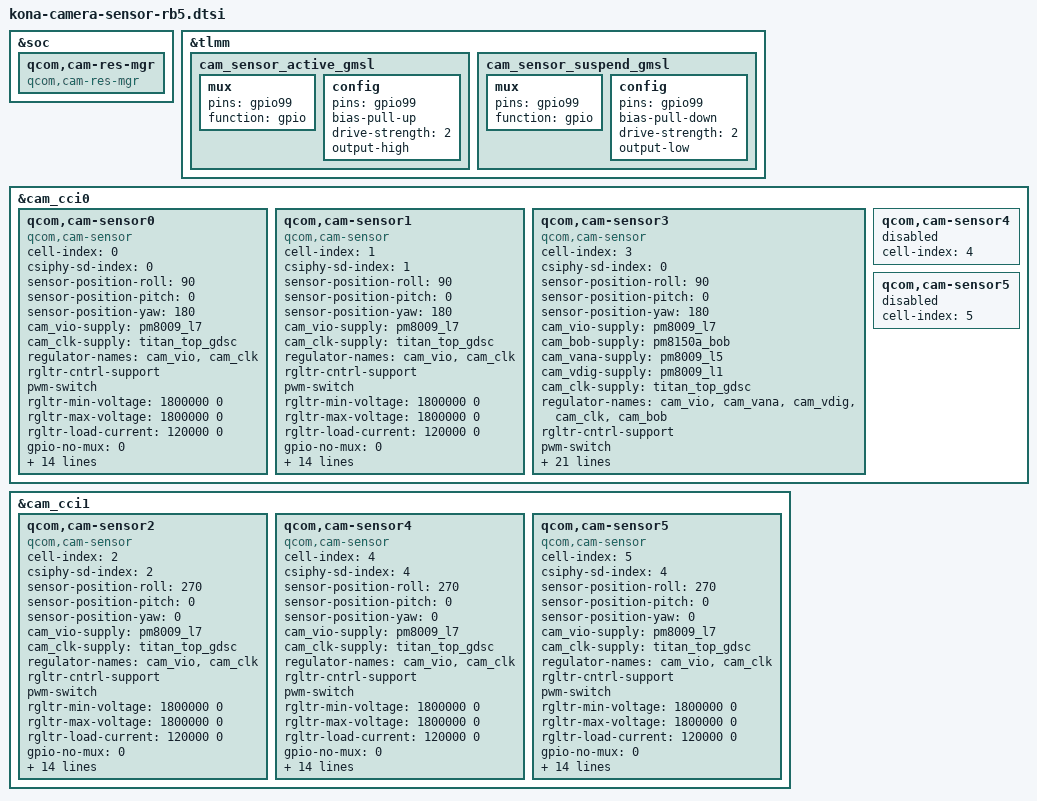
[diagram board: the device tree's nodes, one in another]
&soc {
	qcom,cam-res-mgr {
		compatible = "qcom,cam-res-mgr";
		status = "ok";
	};
};

&tlmm {
	cam_sensor_active_gmsl: cam_sensor_active_gmsl {
		/* RESET */
		mux {
			pins = "gpio99";
			function = "gpio";
		};

		config {
			pins = "gpio99";
			bias-pull-up;
			drive-strength = <2>; /* 2 MA */
			output-high;
		};
	};

	cam_sensor_suspend_gmsl: cam_sensor_suspend_gmsl {
		/* RESET */
		mux {
			pins = "gpio99";
			function = "gpio";
		};

		config {
			pins = "gpio99";
			bias-pull-down; /* PULL DOWN */
			drive-strength = <2>; /* 2 MA */
			output-low;
		};
	};
};

&cam_cci0 {
	qcom,cam-sensor0 {
		cell-index = <0>;
		compatible = "qcom,cam-sensor";
		csiphy-sd-index = <0>;
		sensor-position-roll = <90>;
		sensor-position-pitch = <0>;
		sensor-position-yaw = <180>;
		cam_vio-supply = <&pm8009_l7>;
		cam_clk-supply = <&titan_top_gdsc>;
		regulator-names = "cam_vio", "cam_clk";
		rgltr-cntrl-support;
		pwm-switch;
		rgltr-min-voltage = <1800000 0>;
		rgltr-max-voltage = <1800000 0>;
		rgltr-load-current = <120000 0>;
		gpio-no-mux = <0>;
		pinctrl-names = "cam_default", "cam_suspend";
		pinctrl-0 = <&cam_sensor_mclk0_active
				&cam_sensor_active_rear>;
		pinctrl-1 = <&cam_sensor_mclk0_suspend
				&cam_sensor_suspend_rear>;
		gpios = <&tlmm 94 0>,
			<&tlmm 93 0>;
		gpio-reset = <1>;
		gpio-req-tbl-num = <0 1>;
		gpio-req-tbl-flags = <1 0>;
		gpio-req-tbl-label = "CAMIF_MCLK0",
					"CAM_RESET0";
		sensor-mode = <0>;
		cci-master = <0>;
		status = "ok";
		clocks = <&clock_camcc CAM_CC_MCLK0_CLK>;
		clock-names = "cam_clk";
		clock-cntl-level = "turbo";
		clock-rates = <24000000>;
	};

	qcom,cam-sensor1 {
		cell-index = <1>;
		compatible = "qcom,cam-sensor";
		csiphy-sd-index = <1>;
		sensor-position-roll = <90>;
		sensor-position-pitch = <0>;
		sensor-position-yaw = <180>;
		cam_vio-supply = <&pm8009_l7>;
		cam_clk-supply = <&titan_top_gdsc>;
		regulator-names = "cam_vio", "cam_clk";
		rgltr-cntrl-support;
		pwm-switch;
		rgltr-min-voltage = <1800000 0>;
		rgltr-max-voltage = <1800000 0>;
		rgltr-load-current = <120000 0>;
		gpio-no-mux = <0>;
		pinctrl-names = "cam_default", "cam_suspend";
		pinctrl-0 = <&cam_sensor_mclk1_active
				&cam_sensor_active_rear_aux>;
		pinctrl-1 = <&cam_sensor_mclk1_suspend
				&cam_sensor_suspend_rear_aux>;
		gpios = <&tlmm 95 0>,
			<&tlmm 92 0>;
		gpio-reset = <1>;
		gpio-req-tbl-num = <0 1>;
		gpio-req-tbl-flags = <1 0>;
		gpio-req-tbl-label = "CAMIF_MCLK0",
					"CAM_RESET0";
		sensor-mode = <0>;
		cci-master = <1>;
		status = "ok";
		clocks = <&clock_camcc CAM_CC_MCLK1_CLK>;
		clock-names = "cam_clk";
		clock-cntl-level = "turbo";
		clock-rates = <24000000>;
	};

	qcom,cam-sensor3 {
		cell-index = <3>;
		compatible = "qcom,cam-sensor";
		csiphy-sd-index = <0>;
		sensor-position-roll = <90>;
		sensor-position-pitch = <0>;
		sensor-position-yaw = <180>;
		cam_vio-supply = <&pm8009_l7>;
		cam_bob-supply = <&pm8150a_bob>;
		cam_vana-supply = <&pm8009_l5>;
		cam_vdig-supply = <&pm8009_l1>;
		cam_clk-supply = <&titan_top_gdsc>;
		regulator-names = "cam_vio", "cam_vana", "cam_vdig",
			"cam_clk", "cam_bob";
		rgltr-cntrl-support;
		pwm-switch;
		rgltr-min-voltage = <1800000 2800000 1104000 0 3008000>;
		rgltr-max-voltage = <1800000 3000000 1104000 0 3960000>;
		rgltr-load-current = <120000 80000 1200000 0 2000000>;
		gpio-no-mux = <0>;
		pinctrl-names = "cam_default", "cam_suspend";
		pinctrl-0 = <&cam_sensor_mclk0_active
				&cam_sensor_active_rear>;
		pinctrl-1 = <&cam_sensor_mclk0_suspend
				&cam_sensor_suspend_rear>;
		gpios = <&tlmm 94 0>,
			<&tlmm 93 0>;
		gpio-reset = <1>;
		gpio-req-tbl-num = <0 1>;
		gpio-req-tbl-flags = <1 0>;
		gpio-req-tbl-label = "CAMIF_MCLK0",
					"CAM_RESET0";
		sensor-mode = <0>;
		cci-master = <0>;
		status = "ok";
		clocks = <&clock_camcc CAM_CC_MCLK0_CLK>;
		clock-names = "cam_clk";
		clock-cntl-level = "turbo";
		clock-rates = <24000000>;
	};

	qcom,cam-sensor4 {
		cell-index = <4>;
		status = "disable";
	};

	qcom,cam-sensor5 {
		cell-index = <5>;
		status = "disable";
	};
};

&cam_cci1 {
	qcom,cam-sensor2 {
		cell-index = <2>;
		compatible = "qcom,cam-sensor";
		csiphy-sd-index = <2>;
		sensor-position-roll = <270>;
		sensor-position-pitch = <0>;
		sensor-position-yaw = <0>;
		cam_vio-supply = <&pm8009_l7>;
		cam_clk-supply = <&titan_top_gdsc>;
		regulator-names = "cam_vio", "cam_clk";
		rgltr-cntrl-support;
		pwm-switch;
		rgltr-min-voltage = <1800000 0>;
		rgltr-max-voltage = <1800000 0>;
		rgltr-load-current = <120000 0>;
		gpio-no-mux = <0>;
		pinctrl-names = "cam_default", "cam_suspend";
		pinctrl-0 = <&cam_sensor_mclk2_active
				 &cam_sensor_active_rst2>;
		pinctrl-1 = <&cam_sensor_mclk2_suspend
				 &cam_sensor_suspend_rst2>;
		gpios = <&tlmm 96 0>,
			<&tlmm 78 0>;
		gpio-reset = <1>;
		gpio-req-tbl-num = <0 1>;
		gpio-req-tbl-flags = <1 0>;
		gpio-req-tbl-label = "CAMIF_MCLK2",
					"CAM_RESET2";
		sensor-mode = <0>;
		cci-master = <0>;
		status = "ok";
		clocks = <&clock_camcc CAM_CC_MCLK2_CLK>;
		clock-names = "cam_clk";
		clock-cntl-level = "turbo";
		clock-rates = <24000000>;
	};

	qcom,cam-sensor4 {
		cell-index = <4>;
		compatible = "qcom,cam-sensor";
		csiphy-sd-index = <4>;
		sensor-position-roll = <270>;
		sensor-position-pitch = <0>;
		sensor-position-yaw = <0>;
		cam_vio-supply = <&pm8009_l7>;
		cam_clk-supply = <&titan_top_gdsc>;
		regulator-names = "cam_vio", "cam_clk";
		rgltr-cntrl-support;
		pwm-switch;
		rgltr-min-voltage = <1800000 0>;
		rgltr-max-voltage = <1800000 0>;
		rgltr-load-current = <120000 0>;
		gpio-no-mux = <0>;
		pinctrl-names = "cam_default", "cam_suspend";
		pinctrl-0 = <&cam_sensor_mclk2_active
				 &cam_sensor_active_gmsl>;
		pinctrl-1 = <&cam_sensor_mclk2_suspend
				 &cam_sensor_suspend_gmsl>;
		gpios = <&tlmm 94 0>,
			<&tlmm 99 0>;
		gpio-reset = <1>;
		gpio-req-tbl-num = <0 1>;
		gpio-req-tbl-flags = <1 0>;
		gpio-req-tbl-label = "CAMIF_MCLK2",
					"CAM_RESET4";
		sensor-mode = <0>;
		cci-master = <1>;
		status = "ok";
		clocks = <&clock_camcc CAM_CC_MCLK2_CLK>;
		clock-names = "cam_clk";
		clock-cntl-level = "turbo";
		clock-rates = <24000000>;
	};

	qcom,cam-sensor5 {
		cell-index = <5>;
		compatible = "qcom,cam-sensor";
		csiphy-sd-index = <4>;
		sensor-position-roll = <270>;
		sensor-position-pitch = <0>;
		sensor-position-yaw = <0>;
		cam_vio-supply = <&pm8009_l7>;
		cam_clk-supply = <&titan_top_gdsc>;
		regulator-names = "cam_vio", "cam_clk";
		rgltr-cntrl-support;
		pwm-switch;
		rgltr-min-voltage = <1800000 0>;
		rgltr-max-voltage = <1800000 0>;
		rgltr-load-current = <120000 0>;
		gpio-no-mux = <0>;
		pinctrl-names = "cam_default", "cam_suspend";
		pinctrl-0 = <&cam_sensor_mclk2_active
				 &cam_sensor_active_gmsl>;
		pinctrl-1 = <&cam_sensor_mclk2_suspend
				 &cam_sensor_suspend_gmsl>;
		gpios = <&tlmm 94 0>,
			<&tlmm 99 0>;
		gpio-reset = <1>;
		gpio-req-tbl-num = <0 1>;
		gpio-req-tbl-flags = <1 0>;
		gpio-req-tbl-label = "CAMIF_MCLK2",
					"CAM_RESET4";
		sensor-mode = <0>;
		cci-master = <1>;
		status = "ok";
		clocks = <&clock_camcc CAM_CC_MCLK2_CLK>;
		clock-names = "cam_clk";
		clock-cntl-level = "turbo";
		clock-rates = <24000000>;
	};
};
